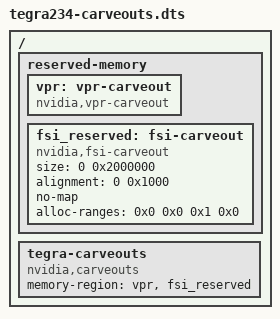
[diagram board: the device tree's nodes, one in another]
// SPDX-License-Identifier: GPL-2.0

/dts-v1/;
/plugin/;

/ {
	fragment@0 {
		target-path = "/";
		__overlay__ {

			reserved-memory {
				#address-cells = <2>;
				#size-cells = <2>;
				ranges;

				vpr: vpr-carveout {
					compatible = "nvidia,vpr-carveout";
					status = "okay";
				};

				fsi_reserved: fsi-carveout {
					compatible = "nvidia,fsi-carveout";
					size = <0 0x2000000>;
					alignment = <0 0x1000>;
					no-map;
					alloc-ranges = <0x0 0x0 0x1 0x0>;
					status = "okay";
				};
			};

			tegra-carveouts {
				compatible = "nvidia,carveouts";
				memory-region = <&vpr &fsi_reserved>;
				status = "okay";
			};
		};
	};
};
